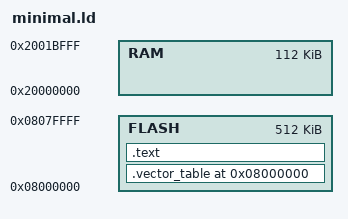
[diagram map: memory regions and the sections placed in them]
/* LabWired NUCLEO-G491RE smoke linker script. */
MEMORY
{
  FLASH : ORIGIN = 0x08000000, LENGTH = 512K
  RAM : ORIGIN = 0x20000000, LENGTH = 112K
}

ENTRY(Reset)

SECTIONS
{
  .vector_table 0x08000000 :
  {
    LONG(0x2001C000); /* Initial SP at the top of the exposed 112 KiB SRAM. */
    LONG(Reset + 1);  /* Reset handler (Thumb). */
  } > FLASH

  .text :
  {
    *(.text*)
    *(.rodata*)
  } > FLASH

  /DISCARD/ :
  {
    *(.ARM.exidx*)
    *(.note.gnu.build-id*)
  }
}
